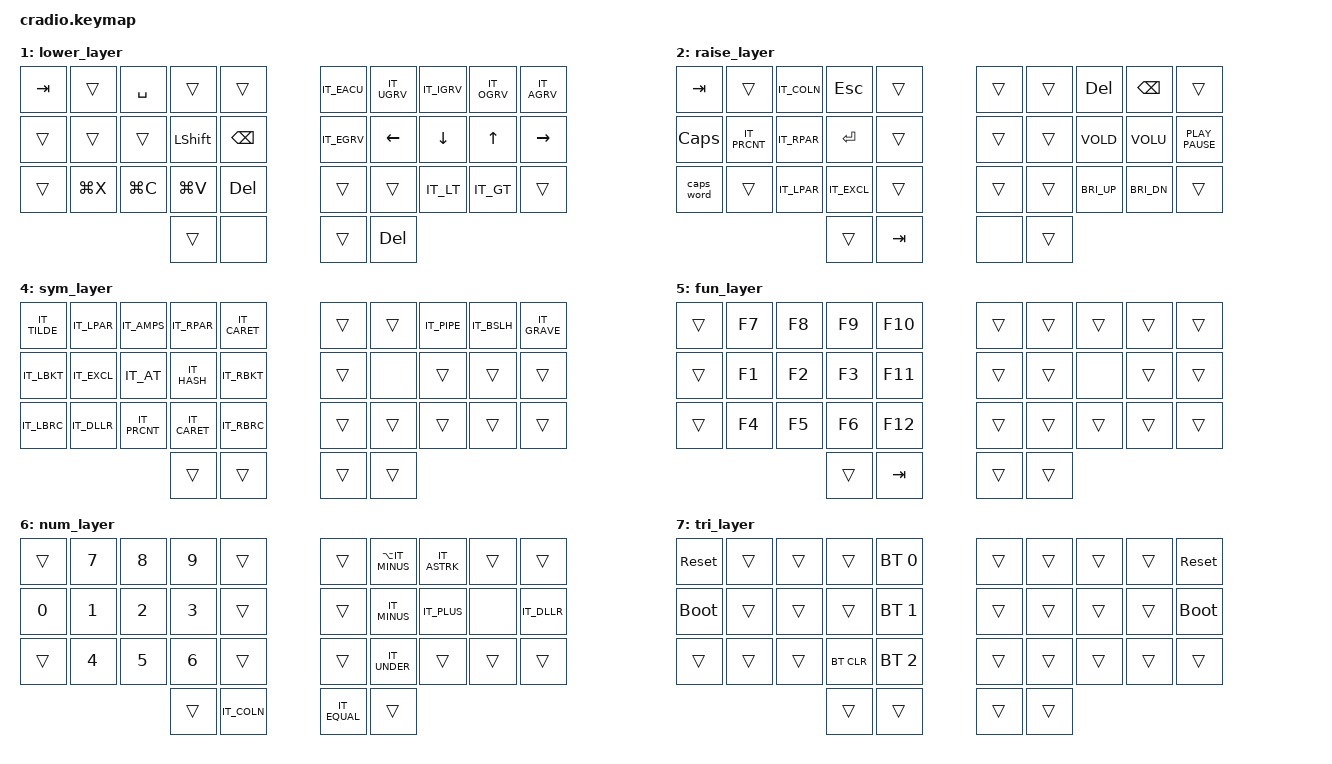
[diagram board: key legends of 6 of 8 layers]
// Copyright (c) 2022 The ZMK Contributors
// SPDX-License-Identifier: MIT

#include <behaviors.dtsi>
#include <dt-bindings/zmk/keys.h>
#include <dt-bindings/zmk/bt.h>
#include "italian.h"

// Home row mods macro
#define HRML(k1,k2,k3,k4) &ht LSHFT k1  &ht LALT k2  &ht LGUI k3  &lt SUP k4
#define HRMLB(k1,k2,k3) &ht LCTRL k1  &ht LGUI k2  &ht LALT k3
#define HRMR(k1,k2,k3,k4) &lt SYM k1  &lt FUN k2  &lt NUM k3  &ht RSHFT k4
#define HRMRB(k1,k2,k3) &ht RALT k1  &ht RGUI k2  &ht RCTRL k3

// Layers
#define DEFAULT 0
#define LOWER   1 
#define RAISE   2
#define SUP     3
#define SYM     4
#define FUN     5
#define NUM     6
#define TRI     7


/ {
     behaviors {
        ht: hold_tap {
            compatible = "zmk,behavior-hold-tap";
            label = "HOMEROW_MODS";
            #binding-cells = <2>;
            tapping-term-ms = <220>;    // <---[[moderate duration]]
            quick-tap-ms = <125>;
            flavor = "tap-preferred";
            bindings = <&kp>, <&kp>;
        };
    };

    combos {
        compatible = "zmk,combos";
        combo_cmd {
            timeout-ms = <70>;
            key-positions = <11 12>;
            bindings = <&mo_fun>;
        };
    };

    ZMK_MACRO(mo_fun,
        wait-ms = <0>;  
        bindings
            = <&macro_press &mo FUN &kp LGUI>
            , <&macro_pause_for_release>
            , <&macro_release &mo FUN &kp LGUI>;
    )

    conditional_layers {
        compatible = "zmk,conditional-layers";
        tri_layer {
            if-layers = <1 2>;
            then-layer = <7>;
        };
    };

    keymap {
        compatible = "zmk,keymap";
        default_layer {
            bindings = <
        //╭──────────┬──────────┬──────────┬──────────┬──────────╮   ╭──────────┬──────────┬──────────┬──────────┬──────────╮
        //│  Q       │  W       │  E       │  R       │  T       │   │  Y       │  U       │  I       │  O       │  P       │            
        //├──────────┼──────────┼──────────┼──────────┼──────────┤   ├──────────┼──────────┼──────────┼──────────┼──────────┤
        //│  A       │  S       │  D       │  F       │  G       │   │  H       │  J       │  K       │  L       │ ' ?      │
        //├──────────┼──────────┼──────────┼──────────┼──────────┤   ├──────────┼──────────┼──────────┼──────────┼──────────┤
        //│  Z       │  X       │  C       │  V       │  B       │   │  N       │  M       │ , ;      │ . :      │ /        │  
        //╰──────────┴──────────┴──────────┼──────────┼──────────┤   ├──────────┼──────────┼──────────┴──────────┴──────────╯
        //                                 │  CMD/ENT │LOWER BSP │   │RAISE SPC │   BSPC   │
        //                                 ╰──────────┴──────────╯   ╰──────────┴──────────╯
            
            &kp IT_Q    &kp IT_W   &kp IT_E   &kp IT_R   &kp IT_T     &kp IT_Y   &kp IT_U   &kp IT_I       &kp IT_O &kp IT_P      

            HRML(IT_A, IT_S, IT_D, IT_F)  &kp IT_G     &kp IT_H   HRMR (IT_J, IT_K, IT_L, IT_QUOT)

            HRMLB(IT_Z, IT_X, IT_C)  &kp IT_V   &kp IT_B     &kp IT_N   &kp IT_M   HRMRB(IT_COMMA, IT_DOT, IT_SLSH)
                                                                        
                                         &mt LGUI ENTER    &lt LOWER BSPC  &lt RAISE SPACE  &kp BSPC
            >;
        };

        lower_layer {
            bindings = <
        //╭──────────┬──────────┬──────────┬──────────┬──────────╮   ╭──────────┬──────────┬──────────┬──────────┬──────────╮
        //│  TAB     │          │  SPACE   │          │          │   │    é     │    ù     │    ì     │    ò     │    à     │     
        //├──────────┼──────────┼──────────┼──────────┼──────────┤   ├──────────┼──────────┼──────────┼──────────┼──────────┤
        //│          │          │          │ SHIFT    │  BSPC    │   │    è     │   LEFT   │   DOWN   │   UP     │   RIGHT  │
        //├──────────┼──────────┼──────────┼──────────┼──────────┤   ├──────────┼──────────┼──────────┼──────────┼──────────┤
        //│          │   CUT    │  COPY    │  PASTE   │  DEL     │   │          │          │    <     │    >     │          │
        //╰──────────┴──────────┴──────────┼──────────┼──────────┤   ├──────────┼──────────┼──────────┴──────────┴──────────╯
        //                                 │          │  ----    │   │          │   DEL    │
        //                                 ╰──────────┴──────────╯   ╰──────────┴──────────╯

           &kp TAB  &trans  &kp SPACE  &trans &trans   &kp IT_EACU &kp IT_UGRV &kp IT_IGRV &kp IT_OGRV &kp IT_AGRV
            
           &trans   &trans   &trans   &kp LSHFT   &kp BSPC    &kp IT_EGRV &kp LEFT    &kp DOWN    &kp UP    &kp RIGHT
          
           &trans      &kp LG(X)  &kp LG(C)  &kp LG(V)   &kp DEL     &trans      &trans      &kp IT_LT &kp IT_GT &trans
          
                                             &trans      &none       &trans      &kp DEL

            >;
        };

        raise_layer {
            bindings = <
        //╭──────────┬──────────┬──────────┬──────────┬──────────╮   ╭──────────┬──────────┬──────────┬──────────┬──────────╮
        //│  TAB     │          │     :    │   ESC    │          │   │          │          │   DEL    │   BSPC   │          │            
        //├──────────┼──────────┼──────────┼──────────┼──────────┤   ├──────────┼──────────┼──────────┼──────────┼──────────┤
        //│  CAPS    │    %     │     )    │   ENT    │          │   │          │          │   VOLD   │   VOLU   │  PLAY    │
        //├──────────┼──────────┼──────────┼──────────┼──────────┤   ├──────────┼──────────┼──────────┼──────────┼──────────┤
        //│  CAPSW   │          │     (    │    !     │          │   │          │          │BRIGHT UP │BRIGHT DOW│          │
        //╰──────────┴──────────┴──────────┼──────────┼──────────┤   ├──────────┼──────────┼──────────┴──────────┴──────────╯
        //                                 │          │  TAB     │   │  ----    │          │
        //                                 ╰──────────┴──────────╯   ╰──────────┴──────────╯

         &kp TAB      &trans      &kp IT_COLN &kp ESC     &trans        &trans     &trans    &kp DEL      &kp BSPC     &trans 

         &kp CAPS    &kp IT_PRCNT &kp IT_RPAR &kp ENTER   &trans        &trans     &trans    &kp VOLD     &kp VOLU     &kp K_PLAY_PAUSE

         &caps_word      &trans      &kp IT_LPAR &kp IT_EXCL &trans        &trans     &trans    &kp C_BRI_UP &kp C_BRI_DN &trans 

                                               &trans    &kp TAB             &none      &trans 
            >;
        };

        sup_layer {
            bindings = <
        //╭──────────┬──────────┬──────────┬──────────┬──────────╮   ╭──────────┬──────────┬──────────┬──────────┬──────────╮
        //│          │  BSPC    │  DEL     │          │          │   │          │          │ Screen   │ ScreenP  │          │
        //├──────────┼──────────┼──────────┼──────────┼──────────┤   ├──────────┼──────────┼──────────┼──────────┼──────────┤
        //│          │          │          │  ----    │          │   │          │          │ Screen C │ ScreenP C│    "     │
        //├──────────┼──────────┼──────────┼──────────┼──────────┤   ├──────────┼──────────┼──────────┼──────────┼──────────┤
        //│          │          │          │          │          │   │          │          │    <     │    >     │    ?     │
        //╰──────────┴──────────┴──────────┼──────────┼──────────┤   ├──────────┼──────────┼──────────┴──────────┴──────────╯
        //                                 │          │   SPACE  │   │          │          │
         
         &trans         &kp BSPC    &kp DEL   &trans      &trans        &trans     &trans   &kp LG(LS(3))  &kp LG(LS(4))      &trans    

         &trans         &trans      &trans    &none       &trans        &trans     &trans   &kp LG(LC(LS(3))) &kp LG(LC(LS(4))) &kp IT_DQUO 

         &trans         &trans      &trans    &trans      &trans        &trans     &trans   &kp IT_LT &kp IT_GT &kp IT_QMARK

                                              &trans      &kp SPACE     &trans     &trans   


            >;
        };

        sym_layer {
            bindings = <
        //╭──────────┬──────────┬──────────┬──────────┬──────────╮   ╭──────────┬──────────┬──────────┬──────────┬──────────╮
        //│    ~     │    (     │    &     │    )     │    ^     │   │          │          │    |     │    \     │    `     │
        //├──────────┼──────────┼──────────┼──────────┼──────────┤   ├──────────┼──────────┼──────────┼──────────┼──────────┤
        //│    {     │    !     │    @     │    #     │    }     │   │          │ ----     │          │          │          │
        //├──────────┼──────────┼──────────┼──────────┼──────────┤   ├──────────┼──────────┼──────────┼──────────┼──────────┤
        //│    [     │    $     │    %     │    ^     │    ]     │   │          │          │          │          │          │
        //╰──────────┴──────────┴──────────┼──────────┼──────────┤   ├──────────┼──────────┼──────────┴──────────┴──────────╯
        //                                 │          │          │   │          │          │
        //                                 ╰──────────┴──────────╯   ╰──────────┴──────────╯

         &kp IT_TILDE &kp IT_LPAR &kp IT_AMPS &kp IT_RPAR &kp IT_CARET  &trans      &trans    &kp IT_PIPE &kp IT_BSLH &kp IT_GRAVE

         &kp IT_LBKT &kp IT_EXCL &kp IT_AT   &kp IT_HASH &kp IT_RBKT  &trans      &none     &trans      &trans      &trans

         &kp IT_LBRC &kp IT_DLLR  &kp IT_PRCNT &kp IT_CARET &kp IT_RBRC  &trans      &trans    &trans      &trans      &trans

                                             &trans      &trans      &trans       &trans      
        
            >;
        };

        
        fun_layer {
            bindings = <
        //╭──────────┬──────────┬──────────┬──────────┬──────────╮   ╭──────────┬──────────┬──────────┬──────────┬──────────╮
        //│          │    F7    │   F8     │    F9    │  F10     │   │          │          │          │          │          │
        //├──────────┼──────────┼──────────┼──────────┼──────────┤   ├──────────┼──────────┼──────────┼──────────┼──────────┤
        //│          │    F1    │   F2     │    F3    │  F11     │   │          │          │  ----    │          │          │
        //├──────────┼──────────┼──────────┼──────────┼──────────┤   ├──────────┼──────────┼──────────┼──────────┼──────────┤
        //│          │    F4    │   F5     │    F6    │  F12     │   │          │          │          │          │          │
        //╰──────────┴──────────┴──────────┼──────────┼──────────┤   ├──────────┼──────────┼──────────┴──────────┴──────────╯
        //                                 │          │  TAB     │   │          │          │
        //                                 ╰──────────┴──────────╯   ╰──────────┴──────────╯

         &trans         &kp F7    &kp F8     &kp F9      &kp F10        &trans     &trans     &trans     &trans    &trans
         
         &trans         &kp F1    &kp F2     &kp F3      &kp F11        &trans     &trans     &none      &trans    &trans

         &trans         &kp F4    &kp F5     &kp F6      &kp F12        &trans     &trans     &trans     &trans    &trans

                                              &trans     &kp TAB        &trans     &trans   


            >;
        };

        num_layer {
            bindings = <
        //╭──────────┬──────────┬──────────┬──────────┬──────────╮   ╭──────────┬──────────┬──────────┬──────────┬──────────╮
        //│          │    7     │    8     │    9     │          │   │          │    –     │    *     │          │          │
        //├──────────┼──────────┼──────────┼──────────┼──────────┤   ├──────────┼──────────┼──────────┼──────────┼──────────┤
        //│    0     │    1     │    2     │    3     │          │   │          │    -     │    +     │  ----    │    $     │
        //├──────────┼──────────┼──────────┼──────────┼──────────┤   ├──────────┼──────────┼──────────┼──────────┼──────────┤
        //│          │    4     │    5     │    6     │          │   │          │    _     │          │          │          │
        //╰──────────┴──────────┴──────────┼──────────┼──────────┤   ├──────────┼──────────┼──────────┴──────────┴──────────╯
        //                                 │          │    :     │   │    =     │          │
        //                                 ╰──────────┴──────────╯   ╰──────────┴──────────╯


         &trans        &kp N7       &kp N8      &kp N9     &trans         &trans    &kp LA(IT_MINUS)  &kp IT_ASTRK &trans    &trans

         &kp N0        &kp N1       &kp N2      &kp N3     &trans         &trans    &kp IT_MINUS  &kp IT_PLUS &none     &kp IT_DLLR
   
         &trans        &kp N4       &kp N5      &kp N6     &trans         &trans    &kp IT_UNDER  &trans      &trans    &trans

                                              &trans    &kp IT_COLN    &kp IT_EQUAL &trans   
            >;
        };

        tri_layer {
            bindings = <
        //╭──────────┬──────────┬──────────┬──────────┬──────────╮   ╭──────────┬──────────┬──────────┬──────────┬──────────╮
        //│ RESET    │          │          │          │PROFILE 0 │   │          │          │          │          │  RESET   │
           &sys_reset  &trans     &trans     &trans    &bt BT_SEL 0    &trans     &trans     &trans     &trans    &sys_reset
        //├──────────┼──────────┼──────────┼──────────┼──────────┤   ├──────────┼──────────┼──────────┼──────────┼──────────┤
        //│BOOTLOADER│          │          │          │PROFILE 1 │   │          │          │          │          │BOOTLOADER│
          &bootloader  &trans     &trans     &trans    &bt BT_SEL 1    &trans     &trans     &trans     &trans    &bootloader
        //├──────────┼──────────┼──────────┼──────────┼──────────┤   ├──────────┼──────────┼──────────┼──────────┼──────────┤
        //│          │          │          │ CLEAR BT │PROFILE 2 │   │          │          │          │          │          │
            &trans     &trans     &trans    &bt BT_CLR &bt BT_SEL 2    &trans     &trans     &trans     &trans     &trans
        //╰──────────┴──────────┴──────────┼──────────┼──────────┤   ├──────────┼──────────┼──────────┴──────────┴──────────╯
                                             &trans     &trans         &trans     &trans
        //                                 ╰──────────┴──────────╯   ╰──────────┴──────────╯
            >;
        };
    };
};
